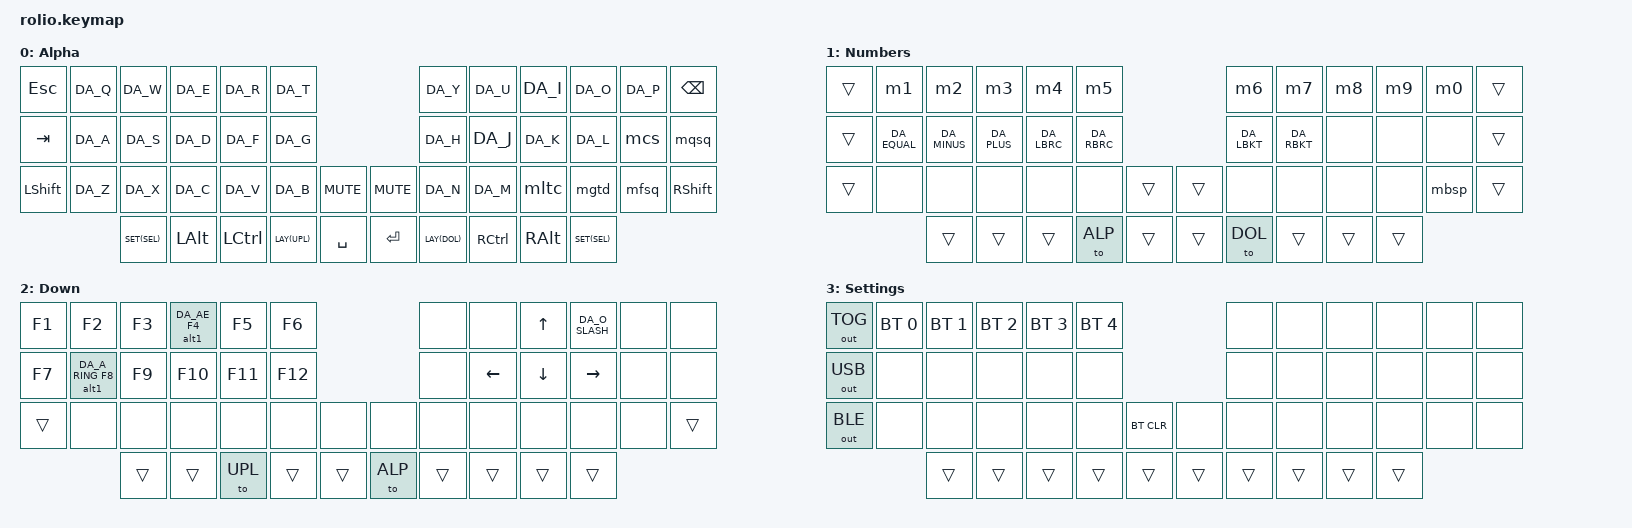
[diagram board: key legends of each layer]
/*
 * Copyright (c) 2020 The ZMK Contributors
 *
 * SPDX-License-Identifier: MIT
 */

#include <behaviors.dtsi>
#include <dt-bindings/zmk/keys.h>
#include <dt-bindings/zmk/bt.h>
#include <dt-bindings/zmk/outputs.h>
#define ZMK_POINTING_DEFAULT_SCRL_VAL 140 // default: 10
#include <dt-bindings/zmk/pointing.h>

#include "keys_da.h"
#include "behaviors.dtsi"
#include "combos.dtsi"

#define ALP  0
#define UPL  1
#define DOL  2
#define SEL  3

#define LAY(layer) &laytt layer layer
#define SET(s)     &setting s LSHIFT
//                  hold        tap
#define DK_F8  &alt1 DA_A_RING   F8
#define DK_F4  &alt1 DA_AE       F4 

#define N_PIPE  RA(LS(EQUAL))
/ {
    keymap {
        compatible = "zmk,keymap";

        default_layer {
            label = "Alpha";
            sensor-bindings = <&s_c &inc_dec_kp C_VOL_UP C_VOL_DN>;
            bindings = <
    &kp ESCAPE  &kp DA_Q    &kp DA_W    &kp DA_E        &kp DA_R    &kp DA_T                              &kp DA_Y  &kp DA_U    &kp DA_I    &kp DA_O    &kp DA_P    &kp BACKSPACE
    &kp TAB     &kp DA_A    &kp DA_S    &kp DA_D        &kp DA_F    &kp DA_G                              &kp DA_H  &kp DA_J    &kp DA_K    &kp DA_L    &mcs        &mqsq
    &kp LSHIFT  &kp DA_Z    &kp DA_X    &kp DA_C        &kp DA_V    &kp DA_B   &kp C_MUTE     &kp C_MUTE  &kp DA_N  &kp DA_M    &mltc       &mgtd       &mfsq       &kp RSHIFT
                            SET(SEL)    &kp LALT        &kp LCTRL   LAY(UPL)   &kp SPACE      &kp ENTER   LAY(DOL)  &kp RCTRL   &kp RALT    SET(SEL)
            >;
        };

        numbers_layer {
            label = "Numbers";
            sensor-bindings = <&s_c &inc_dec_kp C_VOL_UP C_VOL_DN>;
            bindings = <
    &trans  &m1             &m2             &m3         &m4         &m5                                     &m6         &m7         &m8         &m9     &m0     &trans
    &trans  &kp DA_EQUAL    &kp DA_MINUS    &kp DA_PLUS &kp DA_LBRC &kp DA_RBRC                             &kp DA_LBKT &kp DA_RBKT &none       &none   &none   &trans
    &trans  &none           &none           &none       &none       &none       &trans            &trans    &none       &none       &none       &none   &mbsp   &trans
                            &trans          &trans      &trans      &to ALP     &trans            &trans    &to DOL     &trans      &trans     &trans
            >;
        };

        other_layer {
            label = "Down";
            sensor-bindings = <&s_c &inc_dec_kp C_VOL_UP C_VOL_DN>;
            bindings = <
    &kp F1  &kp F2  &kp F3  DK_F4     &kp F5  &kp F6                      &none      &none      &kp UP     &kp DA_O_SLASH   &none   &none
    &kp F7  DK_F8  &kp F9   &kp F10    &kp F11 &kp F12                     &none      &kp LEFT   &kp DOWN   &kp RIGHT        &none   &none
    &trans   &none   &none    &none      &none   &none   &none       &none   &none      &none      &none      &none            &none   &trans
                             &trans     &trans  &to UPL &trans      &trans  &to ALP    &trans     &trans     &trans           &trans
            >; 
        };


        settings_layer {
            label = "Settings";
            sensor-bindings = <&s_c &inc_dec_kp C_VOL_UP C_VOL_DN>;
            bindings = <
    &out OUT_TOG    &bt BT_SEL 0    &bt BT_SEL 1    &bt BT_SEL 2   &bt BT_SEL 3  &bt BT_SEL 4                       &none     &none     &none     &none     &none     &none
    &out OUT_USB    &none           &none           &none         &none        &none                                &none     &none     &none     &none     &none     &none
    &out OUT_BLE    &none           &none           &none         &none        &none         &bt BT_CLR     &none   &none     &none     &none     &none     &none     &none
                                    &trans          &trans        &trans       &trans        &trans         &trans  &trans    &trans    &trans    &trans
            >;
        };

    };
};
